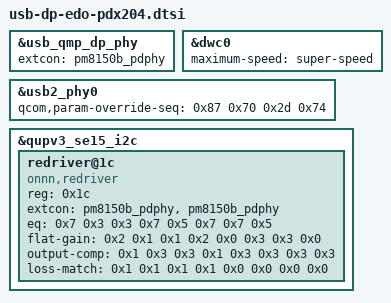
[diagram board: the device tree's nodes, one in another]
/* arch/arm64/boot/dts/somc/usb-dp-edo-pdx204.dtsi
 *
 * This program is free software; you can redistribute it and/or modify
 * it under the terms of the GNU General Public License version 2 and
 * only version 2 as published by the Free Software Foundation.
 *
 * This program is distributed in the hope that it will be useful,
 * but WITHOUT ANY WARRANTY; without even the implied warranty of
 * MERCHANTABILITY or FITNESS FOR A PARTICULAR PURPOSE.  See the
 * GNU General Public License for more details.
 */

&usb_qmp_dp_phy {
	extcon = <&pm8150b_pdphy>;
};

&dwc0 {
	maximum-speed = "super-speed";
};

/* Primary USB port related High Speed PHY */
&usb2_phy0 {
	qcom,param-override-seq =
		<0x87 0x70
		0x2d 0x74>;
};

/* redriver parameter */
&qupv3_se15_i2c {
	#address-cells = <1>;
	#size-cells = <0>;
	status = "ok";
	redriver@1c {
		compatible = "onnn,redriver";
		reg = <0x1c>;
		extcon = <&pm8150b_pdphy>, <&pm8150b_pdphy>;
		eq = /bits/ 8 <
				/* Parameters for USB */
				0x7 0x3 0x3 0x7
				/* Parameters for DP */
				0x5 0x7 0x7 0x5>;
		flat-gain = /bits/ 8 <
				/* Parameters for USB */
				0x2 0x1 0x1 0x2
				/* Parameters for DP */
				0x0 0x3 0x3 0x0>;
		output-comp = /bits/ 8 <
				/* Parameters for USB */
				0x1 0x3 0x3 0x1
				/* Parameters for DP */
				0x3 0x3 0x3 0x3>;
		loss-match = /bits/ 8 <
				/* Parameters for USB */
				0x1 0x1 0x1 0x1
				/* Parameters for DP */
				0x0 0x0 0x0 0x0>;
	};
};
